# ESP32-S2 register map
Vendor: ESPRESSIF SYSTEMS (SHANGHAI) CO., LTD.; Series: ESP32 S-Series; File version: 20
CPU: Xtensa LX7 r0p0, little endian, no MPU, no FPU, 0 interrupt priority bits
Address unit: 32 bits
Registers are 32-bit, read-write, reset 0x0 unless marked. A register's access mark holds for its fields unless they carry their own. Offsets are from the block's base; [hi:lo] are bit positions; lines under a group give offsets from that group; {n}, {i} and the like mark numbered series.

## TIMG0 — Timer Group 0
Base 0x3F41F000
Same registers: TIMG1 0x3F420000
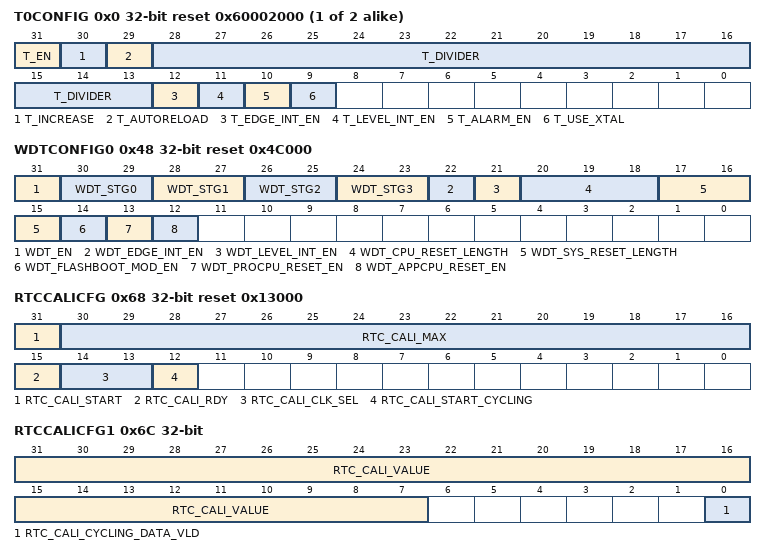
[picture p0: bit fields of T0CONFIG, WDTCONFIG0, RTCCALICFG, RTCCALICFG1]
{0x0+0x24*i} T{i}CONFIG (i=0..1) reset 0x60002000 — Timer {i} configuration register
  [31] T_EN — When set, the timer %s time-base counter is enabled.
  [30] T_INCREASE — When set, the timer %s time-base counter will increment every clock tick. When cleared, the timer %s time-base counter will decrement.
  [29] T_AUTORELOAD — When set, timer %s auto-reload at alarm is enabled.
  [28:13] T_DIVIDER — Timer %s clock (T%s_clk) prescaler value.
  [12] T_EDGE_INT_EN — When set, an alarm will generate an edge type interrupt.
  [11] T_LEVEL_INT_EN — When set, an alarm will generate a level type interrupt.
  [10] T_ALARM_EN — When set, the alarm is enabled. This bit is automatically cleared once an alarm occurs.
  [9] T_USE_XTAL — 1: Use XTAL_CLK as the source clock of timer group. 0: Use APB_CLK as the source clock of timer group.
{0x4+0x24*i} T{i}LO (i=0..1) ro — Timer {i} current value, low 32 bits
  [31:0] T_LO — After writing to TIMG_T%sUPDATE_REG, the low 32 bits of the time-base counter of timer %s can be read here.
{0x8+0x24*i} T{i}HI (i=0..1) ro — Timer {i} current value, high 32 bits
  [31:0] T_HI — After writing to TIMG_T%sUPDATE_REG, the high 32 bits of the time-base counter of timer %s can be read here.
{0xC+0x24*i} T{i}UPDATE (i=0..1) — Write to copy current timer value to TIMG_T{i}LO_REG or TIMGn_T{i}HI_REG
  [31] T_UPDATE — After writing 0 or 1 to TIMG_T%sUPDATE_REG, the counter value is latched.
{0x10+0x24*i} T{i}ALARMLO (i=0..1) — Timer {i} alarm value, low 32 bits
  [31:0] T_ALARM_LO — Timer %s alarm trigger time-base counter value, low 32 bits.
{0x14+0x24*i} T{i}ALARMHI (i=0..1) — Timer {i} alarm value, high bits
  [31:0] T_ALARM_HI — Timer %s alarm trigger time-base counter value, high 32 bits.
{0x18+0x24*i} T{i}LOADLO (i=0..1) — Timer {i} reload value, low 32 bits
  [31:0] T_LOAD_LO — Low 32 bits of the value that a reload will load onto timer %s time-base counter.
{0x1C+0x24*i} T{i}LOADHI (i=0..1) — Timer {i} reload value, high 32 bits
  [31:0] T_LOAD_HI — High 32 bits of the value that a reload will load onto timer %s time-base counter.
{0x20+0x24*i} T{i}LOAD (i=0..1) wo — Write to reload timer from TIMG_T{i}LOADLO_REG or TIMG_T{i}LOADHI_REG
  [31:0] T_LOAD — Write any value to trigger a timer %s time-base counter reload.
0x48 WDTCONFIG0 reset 0x4C000 — Watchdog timer configuration register
  [31] WDT_EN — When set, MWDT is enabled.
  [30-2n:29-2n] WDT_STG{n} (n=0..3) — Stage {n} configuration. 0: off. 1: interrupt. 2: reset CPU. 3: reset system.
  [22] WDT_EDGE_INT_EN — When set, an edge type interrupt will occur at the timeout of a stage configured to generate an interrupt.
  [21] WDT_LEVEL_INT_EN — When set, a level type interrupt will occur at the timeout of a stage configured to generate an interrupt.
  [20:18] WDT_CPU_RESET_LENGTH — CPU reset signal length selection. 0: 100 ns. 1: 200 ns. 2: 300 ns. 3: 400 ns. 4: 500 ns. 5: 800 ns. 6: 1.6 us. 7: 3.2 us.
  [17:15] WDT_SYS_RESET_LENGTH — System reset signal length selection. 0: 100 ns. 1: 200 ns. 2: 300 ns. 3: 400 ns. 4: 500 ns. 5: 800 ns. 6: 1.6 us. 7: 3.2 us.
  [14] WDT_FLASHBOOT_MOD_EN — When set, Flash boot protection is enabled.
  [13] WDT_PROCPU_RESET_EN — WDT reset CPU enable.
  [12] WDT_APPCPU_RESET_EN — Reserved.
0x4C WDTCONFIG1 reset 0x10000 — Watchdog timer prescaler register
  [31:16] WDT_CLK_PRESCALER — MWDT clock prescaler value. MWDT clock period = 12.5 ns * TIMG_WDT_CLK_PRESCALE.
0x50 WDTCONFIG2 reset 0x18CBA80 — Watchdog timer stage 0 timeout value
  [31:0] WDT_STG0_HOLD — Stage 0 timeout value, in MWDT clock cycles.
0x54 WDTCONFIG3 reset 0x7FFFFFF — Watchdog timer stage 1 timeout value
  [31:0] WDT_STG1_HOLD — Stage 1 timeout value, in MWDT clock cycles.
0x58 WDTCONFIG4 reset 0xFFFFF — Watchdog timer stage 2 timeout value
  [31:0] WDT_STG2_HOLD — Stage 2 timeout value, in MWDT clock cycles.
0x5C WDTCONFIG5 reset 0xFFFFF — Watchdog timer stage 3 timeout value
  [31:0] WDT_STG3_HOLD — Stage 3 timeout value, in MWDT clock cycles.
0x60 WDTFEED wo — Write to feed the watchdog timer
  [31:0] WDT_FEED — Write any value to feed the MWDT.
0x64 WDTWPROTECT reset 0x50D83AA1 — Watchdog write protect register
  [31:0] WDT_WKEY — If the register contains a different value than its reset value, write protection is enabled.
0x68 RTCCALICFG access per field reset 0x13000 — RTC calibration configuration register
  [31] RTC_CALI_START rw — Set this bit to starts calibration.
  [30:16] RTC_CALI_MAX rw — Calibration time, in cycles of the clock to be calibrated.
  [15] RTC_CALI_RDY ro — Set this bit to mark the completion of calibration.
  [14:13] RTC_CALI_CLK_SEL rw — Used to select the clock to be calibrated. 0: RTC_CLK. 1: RTC20M_D256_CLK. 2: XTAL32K_CLK.
  [12] RTC_CALI_START_CYCLING rw — When set, periodic calibration is enabled.
0x6C RTCCALICFG1 ro — RTC calibration configuration register 1
  [31:7] RTC_CALI_VALUE — Calibration value when cycles of clock to be calibrated reach TIMG_RTC_CALI_MAX, in unit of XTAL_CLK clock cycles.
  [0] RTC_CALI_CYCLING_DATA_VLD — Periodic calibration valid signal.
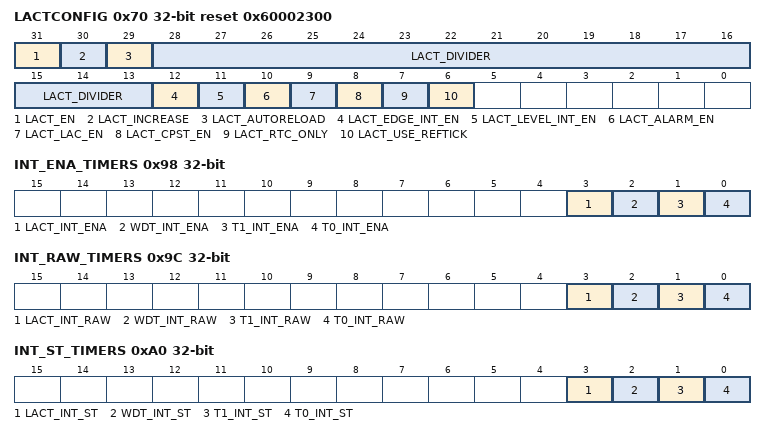
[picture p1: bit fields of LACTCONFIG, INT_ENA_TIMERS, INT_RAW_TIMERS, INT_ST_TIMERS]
0x70 LACTCONFIG reset 0x60002300 — LACT configuration register
  [31] LACT_EN — Reserved.
  [30] LACT_INCREASE — Reserved.
  [29] LACT_AUTORELOAD — Reserved.
  [28:13] LACT_DIVIDER — Reserved.
  [12] LACT_EDGE_INT_EN — Reserved.
  [11] LACT_LEVEL_INT_EN — Reserved.
  [10] LACT_ALARM_EN — Reserved.
  [9] LACT_LAC_EN — Reserved.
  [8] LACT_CPST_EN — Reserved.
  [7] LACT_RTC_ONLY — Reserved.
  [6] LACT_USE_REFTICK — Reserved.
0x74 LACTRTC
  [31:6] LACT_RTC_STEP_LEN — Reserved.
0x78 LACTLO ro — LACT low register
  [31:0] LACT_LO — Reserved.
0x7C LACTHI ro — LACT high register
  [31:0] LACT_HI — Reserved.
0x80 LACTUPDATE wo
  [31:0] LACT_UPDATE — Reserved.
0x84 LACTALARMLO — LACT alarm low register
  [31:0] LACT_ALARM_LO — Reserved.
0x88 LACTALARMHI — LACT alarm high register
  [31:0] LACT_ALARM_HI — Reserved.
0x8C LACTLOADLO — LACT load low register
  [31:0] LACT_LOAD_LO — Reserved.
0x90 LACTLOADHI — Timer LACT load high register
  [31:0] LACT_LOAD_HI — Reserved.
0x94 LACTLOAD wo — Timer LACT load register
  [31:0] LACT_LOAD — Reserved.
0x98 INT_ENA_TIMERS — Interrupt enable bits
  [3] LACT_INT_ENA — The interrupt enable bit for the TIMG_LACT_INT interrupt.
  [2] WDT_INT_ENA — The interrupt enable bit for the TIMG_WDT_INT interrupt.
  [1] T1_INT_ENA — The interrupt enable bit for the TIMG_T1_INT interrupt.
  [0] T0_INT_ENA — The interrupt enable bit for the TIMG_T0_INT interrupt.
0x9C INT_RAW_TIMERS ro — Raw interrupt status
  [3] LACT_INT_RAW — The raw interrupt status bit for the TIMG_LACT_INT interrupt.
  [2] WDT_INT_RAW — The raw interrupt status bit for the TIMG_WDT_INT interrupt.
  [1] T1_INT_RAW — The raw interrupt status bit for the TIMG_T1_INT interrupt.
  [0] T0_INT_RAW — The raw interrupt status bit for the TIMG_T0_INT interrupt.
0xA0 INT_ST_TIMERS ro — Masked interrupt status
  [3] LACT_INT_ST — The masked interrupt status bit for the TIMG_LACT_INT interrupt.
  [2] WDT_INT_ST — The masked interrupt status bit for the TIMG_WDT_INT interrupt.
  [1] T1_INT_ST — The masked interrupt status bit for the TIMG_T1_INT interrupt.
  [0] T0_INT_ST — The masked interrupt status bit for the TIMG_T0_INT interrupt.
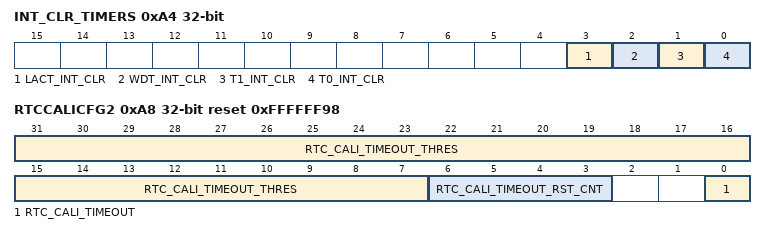
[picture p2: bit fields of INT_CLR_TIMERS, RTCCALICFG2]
0xA4 INT_CLR_TIMERS wo — Interrupt clear bits
  [3] LACT_INT_CLR — Set this bit to clear the TIMG_LACT_INT interrupt.
  [2] WDT_INT_CLR — Set this bit to clear the TIMG_WDT_INT interrupt.
  [1] T1_INT_CLR — Set this bit to clear the TIMG_T1_INT interrupt.
  [0] T0_INT_CLR — Set this bit to clear the TIMG_T0_INT interrupt.
0xA8 RTCCALICFG2 access per field reset 0xFFFFFF98 — Timer group calibration register
  [31:7] RTC_CALI_TIMEOUT_THRES rw — Threshold value for the RTC calibration timer. If the calibration timer's value exceeds this threshold, a timeout is triggered.
  [6:3] RTC_CALI_TIMEOUT_RST_CNT rw — Cycles that release calibration timeout reset
  [0] RTC_CALI_TIMEOUT ro — RTC calibration timeout indicator
0xF8 TIMERS_DATE reset 0x1907261 — Version control register
  [27:0] TIMERS_DATE — Version control register.
0xFC REGCLK — Timer group clock gate register
  [31] CLK_EN — Register clock gate signal. 1: Registers can be read and written to by software. 0: Registers can not be read or written to by software.
